AUTOSAR XML (schema 4-2-2)
standard types defined: uint8, uint16, sint8
package /AUTOSAR/Components
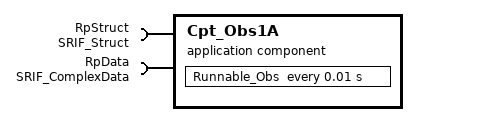
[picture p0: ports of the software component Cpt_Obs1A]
  application sw component type Cpt_Obs1A
    require port RpStruct: nonqueued-receiver-com-spec{data-element=dataElementsStructA, init-value=fields=[0, 0, 0, 0]}, required-interface=SRIF_Struct
    require port RpData: required-interface=SRIF_ComplexData
      required-com-specs:
        data-element=dataElementPrimitive, external-replacement=dataElementPrimitive, init-value=0
        data-element=dataElementStruct, init-value=fields=[0, 1, 2]
        data-element=dataElementArray, init-value=[0]
        data-element=dataElementStructArray, init-value=fields=[0]
    behavior IbObs
      timing event timingEvent_10: start-on-event=Runnable_Obs, period=0.01
      runnable Runnable_Obs: symbol=AppRunnable_Obs
        data-read-access:
          5 x access:
            dataReadAccess_Primitive: accessed-variable=RpData.dataElementPrimitive
            dataReadAccess_Array: accessed-variable=RpData.dataElementArray
            dataReadAccess_Struct: accessed-variable=RpData.dataElementStruct
            dataReadAccess_StructArray: accessed-variable=RpData.dataElementStructArray
            dataReadAccess_StructA: accessed-variable=RpStruct.dataElementsStructA
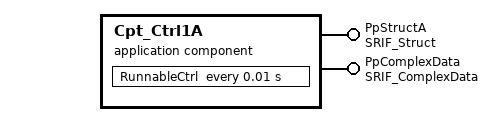
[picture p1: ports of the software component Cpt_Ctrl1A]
  application sw component type Cpt_Ctrl1A
    provide port PpStructA: provided-interface=SRIF_Struct
    provide port PpComplexData: provided-interface=SRIF_ComplexData
    behavior IbCtrl
      timing event timingEvent_10: start-on-event=RunnableCtrl, period=0.01
      runnable RunnableCtrl: symbol=AppRunnableCtrl
        data-write-access:
          5 x access:
            dataWriteAccess_Primitive: accessed-variable=PpComplexData.dataElementPrimitive
            dataWriteAccess_Array: accessed-variable=PpComplexData.dataElementArray
            dataWriteAccess_Struct: accessed-variable=PpComplexData.dataElementStruct
            dataWriteAccess_StructArray: accessed-variable=PpComplexData.dataElementStructArray
            dataWriteAccess_StructA: accessed-variable=PpStructA.dataElementsStructA
package /AUTOSAR/Compositions
  composition sw component type BottomComposition
    component Cpt_Ctrl1A_Prototype: type=Cpt_Ctrl1A
    component Cpt_Obs1A_Prototype: type=Cpt_Obs1A
    connect Cpt_Ctrl1A_Prototype.PpStructA -> Cpt_Obs1A_Prototype.RpStruct
    connect Cpt_Ctrl1A_Prototype.PpComplexData -> Cpt_Obs1A_Prototype.RpData
  composition sw component type TopComposition
    component BottomComposition: type=BottomComposition
package /AUTOSAR/SwcImplementations
  swc implementation swcImplementation_CptObs: behavior=IbObs
  swc implementation swcImplementation_CptCtrl: behavior=IbCtrl
package /AUTOSAR/System
  system system_0
    system mapping SystemMapping_0: sender-receiver-to-signal-group-mapping{data-element=BottomComposition.Cpt_Ctrl1A_Prototype.rootSwCompositionPrototype_0.PpStructA.dataElementsStructA, signal-group=Group_StructA_Msg_StructA, type-mapping=sender-rec-record-type-mapping=record-element-mappings=[{implementation-record-element=Crc_Uint8, system-signal=Signal_DATA8_Msg_StructA}, {implementation-record-element=Data_Uint16, system-signal=Signal_Counter_Msg_StructA}, {implementation-record-element=Counter_Uint8, system-signal=Signal_CRC_Msg_StructA}, {implementation-record-element=Data_Uint8, system-signal=Signal_DATA16_Msg_StructA}]}
      sw-impl-mappings:
        swc to impl mapping CptReceiverPrototypeImplMapping: component-implementation=swcImplementation_CptObs, component=rootSwCompositionPrototype_0.BottomComposition.Cpt_Obs1A_Prototype.Cpt_Obs1A_Prototype
        swc to impl mapping CptSenderPrototypeImplMapping: component-implementation=swcImplementation_CptCtrl, component=rootSwCompositionPrototype_0.BottomComposition.Cpt_Ctrl1A_Prototype.Cpt_Ctrl1A_Prototype
      sw-mappings:
        swc to ecu mapping ECUA_SwcToEcuMapping: ecu-instance=ECUA
          component:
            rootSwCompositionPrototype_0.BottomComposition.Cpt_Obs1A_Prototype.Cpt_Obs1A_Prototype
            rootSwCompositionPrototype_0.BottomComposition.Cpt_Ctrl1A_Prototype.Cpt_Ctrl1A_Prototype
    root-software-compositions:
      root sw composition prototype rootSwCompositionPrototype_0: software-composition=TopComposition
package /AUTOSAR/Interfaces
  sender receiver interface SRIF_Struct
    data dataElementsStructA: type=StructA
  sender receiver interface SRIF_ComplexData
    4 x data:
      dataElementPrimitive: type=PrimitiveUint16
      dataElementArray: type=ArrayUint8
      dataElementStruct: type=StructA
      dataElementStructArray: type=StructArray
package /AUTOSAR/DataTypes
  4 x impl type:
    StructA: category=STRUCTURE
      4 x element, all with category=VALUE:
        Crc_Uint8: base-type=uint8
        Data_Uint16: base-type=uint16
        Counter_Uint8: base-type=uint8
        Data_Uint8: base-type=uint8
    StructArray: category=STRUCTURE
      element Arraydata: implementation-data-type=ArrayUint8
      element dataUint8: category=VALUE, base-type=uint8
    PrimitiveUint16: category=VALUE, base-type=uint16
    ArrayUint8: category=ARRAY
      element subElement: category=VALUE, array-size=10, base-type=uint8
package /SystemInfo/CanClusters
  can cluster CanCluster_0: protocol-name=CAN
    can physical channel CanChannel_0: comm-connectors=CanChannel_0_ECUA_conn
      frame Msg_StructA: id 0x302, from ECUA, frame-length=8, can-addressing-mode=STANDARD
        pdu Msg_StructA: length=8, transmission-mode-conditions=[Signal_DATA8_Msg_StructA, Signal_DATA16_Msg_StructA, Signal_Counter_Msg_StructA, Signal_CRC_Msg_StructA], transmission-mode-true-timing=cyclic-timing=time-period=0.1
          signal Signal_CRC_Msg_StructA: start 0, 8 bit, big-endian, base-type=uint8, update-indication-bit-position=-1
          signal Signal_DATA16_Msg_StructA: start 24, 16 bit, big-endian, base-type=uint16, update-indication-bit-position=-1
          mapping Group_StructA_Msg_StructA: i-signal-group=Group_StructA_Msg_StructA, update-indication-bit-position=-1
          signal Signal_DATA8_Msg_StructA: start 32, 8 bit, little-endian, base-type=sint8, update-indication-bit-position=-1
          signal Signal_Counter_Msg_StructA: start 12, 4 bit, big-endian, base-type=uint8, update-indication-bit-position=-1
package /SystemInfo/ISignals
  i signal group Group_StructA_Msg_StructA: i-signal=[Signal_DATA8_Msg_StructA, Signal_Counter_Msg_StructA, Signal_CRC_Msg_StructA, Signal_DATA16_Msg_StructA], system-signal-group=Group_StructA_Msg_StructA
package /SystemInfo/EcuInstances
  ecu instance ECUA: com-configuration-gw-time-base=0.005, com-configuration-rx-time-base=0.005, com-configuration-tx-time-base=0.005, sleep-mode-supported=false, wake-up-over-bus-supported=false
    can communication controller CanChannel_0_ECUA: wake-up-by-controller-supported=false, can-controller-attributes=can-controller-configuration={sync-jump-width=0, time-seg-1=20, time-seg-2=10}
    can communication connector CanChannel_0_ECUA_conn: comm-controller=CanChannel_0_ECUA
